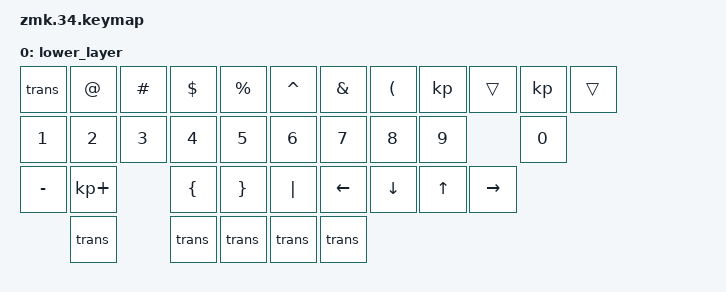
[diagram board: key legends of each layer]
#include <behaviors.dtsi>
#include <dt-bindings/zmk/keys.h>
#include <dt-bindings/zmk/bt.h>
#include <dt-bindings/zmk/outputs.h>

#define DEFAULT  0
#define LOWER    1


/ {
    conditional_layers {
        compatible = "zmk,conditional-layers";
        tri_layer {
            if-layers = <1 2>;
            then-layer = <3>;
        };
    };
};

/ {
    keymap {
        compatible = "zmk,keymap";

        default_layer {
            bindings = <
    &kp ESC  &kp P  &kp Y  &kp F   &kp G    &kp C    &kp H    &kp L     &mo LOWER  &kp BSPC
    &kp A    &kp O  &kp E  &kp U   &kp I    &kp D    &kp R    &kp T     &kp N      &kp S   
    &kp Q    &kp J  &kp K  &kp X   &kp B    &kp M    &kp W    &kp V     &kp Z    
             &kp LSHIFT &kp LCTRL           &kp RET  &kp SPACE &kp LALT
         
        };

        lower_layer {
            bindings = <
    &kp trans &kp AT &kp HASH &kp DLLR &kp PRCNT &kp CARET &kp AMPS &kp LPAR &kp &trans &kp &trans
    &kp N1    &kp N2 &kp N3   &kp N4   &kp N5    &kp N6    &kp N7   &kp N8   &kp N9     &kp N0
     &kp MINUS &kp KP_PLUS &kp LBRC &kp RBRC &kp PIPE &kp LEFT &kp DOWN &kp UP &kp RIGHT 
                &kp trans &kp trans &kp trans &kp trans &kp trans;
            >;
        };
    };
};
